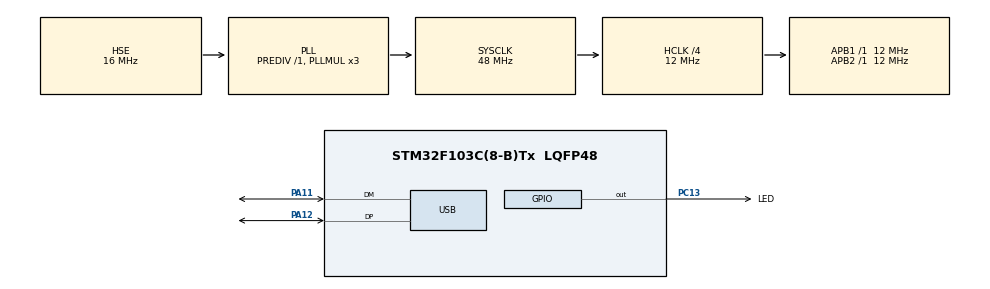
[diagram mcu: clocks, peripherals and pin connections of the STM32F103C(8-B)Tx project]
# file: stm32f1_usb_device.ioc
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FREERTOS.Tasks01=defaultTask,0,128,StartDefaultTask,Default
Mcu.Family=STM32F1
Mcu.Name=STM32F103C(8-B)Tx
Mcu.Package=LQFP48
NVIC.PriorityGroup=NVIC_PRIORITYGROUP_4
NVIC.TIM2_IRQn=true\:0\:0\:false\:false\:true\:false
NVIC.TIM3_IRQn=true\:0\:0\:false\:false\:true\:false
NVIC.TimeBase=TIM3_IRQn
NVIC.TimeBaseIP=TIM3
NVIC.USB_LP_CAN1_RX0_IRQn=true\:5\:0\:false\:false\:true\:true
PA11.Mode=Device
PA11.Signal=USB_DM
PA12.Mode=Device
PA12.Signal=USB_DP
PA13.Mode=Serial_Wire
PA13.Signal=SYS_JTMS-SWDIO
PA14.Mode=Serial_Wire
PA14.Signal=SYS_JTCK-SWCLK
PC13-TAMPER-RTC.GPIO_Label=LED
PC13-TAMPER-RTC.GPIO_Speed=GPIO_SPEED_FREQ_HIGH
PC13-TAMPER-RTC.Signal=GPIO_Output
PD0-OSC_IN.Mode=HSE-External-Oscillator
PD0-OSC_IN.Signal=RCC_OSC_IN
PD1-OSC_OUT.Mode=HSE-External-Oscillator
PD1-OSC_OUT.Signal=RCC_OSC_OUT
ProjectManager.HeapSize=0x200
ProjectManager.StackSize=0x400
ProjectManager.TargetToolchain=EWARM
RCC.AHBCLKDivider=RCC_SYSCLK_DIV4
RCC.AHBFreq_Value=12000000
RCC.APB1Freq_Value=12000000
RCC.APB1TimFreq_Value=12000000
RCC.APB2Freq_Value=12000000
RCC.APB2TimFreq_Value=12000000
RCC.HCLKFreq_Value=12000000
RCC.HSE_VALUE=16000000
RCC.HSIState=RCC_HSI_ON
RCC.PLLMUL=RCC_PLL_MUL3
RCC.PLLSourceVirtual=RCC_PLLSOURCE_HSE
RCC.SYSCLKFreq_VALUE=48000000
RCC.SYSCLKSource=RCC_SYSCLKSOURCE_PLLCLK
RCC.USBFreq_Value=48000000
TIM2.Period=500
TIM2.Prescaler=12000
USB_DEVICE.CLASS_NAME_FS=CDC
USB_DEVICE.USBD_HandleTypeDef=hUsbDeviceFS
USB_DEVICE.VirtualMode=Cdc
USB_DEVICE.VirtualModeFS=Cdc_FS
VP_FREERTOS_VS_ENABLE.Mode=Enabled
VP_SYS_VS_tim3.Mode=TIM3
VP_TIM2_VS_ClockSourceINT.Mode=Internal
VP_USB_DEVICE_VS_USB_DEVICE_CDC_FS.Mode=CDC_FS
board=stm32f1_usb_device

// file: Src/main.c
/**
  ******************************************************************************
  * File Name          : main.c
  * Description        : Main program body
  ******************************************************************************
  *
  * COPYRIGHT(c) 2016 STMicroelectronics
  *
  * Redistribution and use in source and binary forms, with or without modification,
  * are permitted provided that the following conditions are met:
  *   1. Redistributions of source code must retain the above copyright notice,
  *      this list of conditions and the following disclaimer.
  *   2. Redistributions in binary form must reproduce the above copyright notice,
  *      this list of conditions and the following disclaimer in the documentation
  *      and/or other materials provided with the distribution.
  *   3. Neither the name of STMicroelectronics nor the names of its contributors
  *      may be used to endorse or promote products derived from this software
  *      without specific prior written permission.
  *
  * THIS SOFTWARE IS PROVIDED BY THE COPYRIGHT HOLDERS AND CONTRIBUTORS "AS IS"
  * AND ANY EXPRESS OR IMPLIED WARRANTIES, INCLUDING, BUT NOT LIMITED TO, THE
  * IMPLIED WARRANTIES OF MERCHANTABILITY AND FITNESS FOR A PARTICULAR PURPOSE ARE
  * DISCLAIMED. IN NO EVENT SHALL THE COPYRIGHT HOLDER OR CONTRIBUTORS BE LIABLE
  * FOR ANY DIRECT, INDIRECT, INCIDENTAL, SPECIAL, EXEMPLARY, OR CONSEQUENTIAL
  * DAMAGES (INCLUDING, BUT NOT LIMITED TO, PROCUREMENT OF SUBSTITUTE GOODS OR
  * SERVICES; LOSS OF USE, DATA, OR PROFITS; OR BUSINESS INTERRUPTION) HOWEVER
  * CAUSED AND ON ANY THEORY OF LIABILITY, WHETHER IN CONTRACT, STRICT LIABILITY,
  * OR TORT (INCLUDING NEGLIGENCE OR OTHERWISE) ARISING IN ANY WAY OUT OF THE USE
  * OF THIS SOFTWARE, EVEN IF ADVISED OF THE POSSIBILITY OF SUCH DAMAGE.
  *
  ******************************************************************************
  */
#include "stm32f1xx_hal.h"
#include "cmsis_os.h"
#include "usb_device.h"

TIM_HandleTypeDef htim2;

osThreadId defaultTaskHandle;

/* USER CODE BEGIN PV */
/* Private variables ---------------------------------------------------------*/

/* USER CODE END PV */

void SystemClock_Config(void);
void Error_Handler(void);
static void MX_GPIO_Init(void);
static void MX_TIM2_Init(void);
void StartDefaultTask(void const * argument);

/* USER CODE BEGIN PFP */
/* Private function prototypes -----------------------------------------------*/

/* USER CODE END PFP */

int main(void)
{

	/* MCU Configuration----------------------------------------------------------*/

	/* Reset of all peripherals, Initializes the Flash interface and the Systick. */
	HAL_Init();

	/* Configure the system clock */
	SystemClock_Config();

	/* Initialize all configured peripherals */
	MX_GPIO_Init();
	MX_TIM2_Init();

	/* Create the thread(s) */
	/* definition and creation of defaultTask */
	osThreadDef(defaultTask, StartDefaultTask, osPriorityNormal, 0, 128);
	defaultTaskHandle = osThreadCreate(osThread(defaultTask), NULL);

	/* Start scheduler */
	osKernelStart();

	/* We should never get here as control is now taken by the scheduler */

	/* Infinite loop */
	while (1) {

	}

}

/** System Clock Configuration
*/
void SystemClock_Config(void)
{

	RCC_OscInitTypeDef RCC_OscInitStruct;
	RCC_ClkInitTypeDef RCC_ClkInitStruct;
	RCC_PeriphCLKInitTypeDef PeriphClkInit;

	RCC_OscInitStruct.OscillatorType = RCC_OSCILLATORTYPE_HSE;
	RCC_OscInitStruct.HSEState = RCC_HSE_ON;
	RCC_OscInitStruct.HSEPredivValue = RCC_HSE_PREDIV_DIV1;
	RCC_OscInitStruct.PLL.PLLState = RCC_PLL_ON;
	RCC_OscInitStruct.PLL.PLLSource = RCC_PLLSOURCE_HSE;
	RCC_OscInitStruct.PLL.PLLMUL = RCC_PLL_MUL3;
	if (HAL_RCC_OscConfig(&RCC_OscInitStruct) != HAL_OK) {
		Error_Handler();
	}

	RCC_ClkInitStruct.ClockType = RCC_CLOCKTYPE_HCLK|RCC_CLOCKTYPE_SYSCLK
								  |RCC_CLOCKTYPE_PCLK1|RCC_CLOCKTYPE_PCLK2;
	RCC_ClkInitStruct.SYSCLKSource = RCC_SYSCLKSOURCE_PLLCLK;
	RCC_ClkInitStruct.AHBCLKDivider = RCC_SYSCLK_DIV4;
	RCC_ClkInitStruct.APB1CLKDivider = RCC_HCLK_DIV1;
	RCC_ClkInitStruct.APB2CLKDivider = RCC_HCLK_DIV1;
	if (HAL_RCC_ClockConfig(&RCC_ClkInitStruct, FLASH_LATENCY_0) != HAL_OK) {
		Error_Handler();
	}

	PeriphClkInit.PeriphClockSelection = RCC_PERIPHCLK_USB;
	PeriphClkInit.UsbClockSelection = RCC_USBCLKSOURCE_PLL;
	if (HAL_RCCEx_PeriphCLKConfig(&PeriphClkInit) != HAL_OK) {
		Error_Handler();
	}

	HAL_SYSTICK_Config(HAL_RCC_GetHCLKFreq()/1000);

	HAL_SYSTICK_CLKSourceConfig(SYSTICK_CLKSOURCE_HCLK);

	/* SysTick_IRQn interrupt configuration */
	HAL_NVIC_SetPriority(SysTick_IRQn, 15, 0);
}

/* TIM2 init function */
static void MX_TIM2_Init(void)
{

	TIM_ClockConfigTypeDef sClockSourceConfig;
	TIM_MasterConfigTypeDef sMasterConfig;

	htim2.Instance = TIM2;
	htim2.Init.Prescaler = 12000;
	htim2.Init.CounterMode = TIM_COUNTERMODE_UP;
	htim2.Init.Period = 500;
	htim2.Init.ClockDivision = TIM_CLOCKDIVISION_DIV1;
	if (HAL_TIM_Base_Init(&htim2) != HAL_OK) {
		Error_Handler();
	}

	sClockSourceConfig.ClockSource = TIM_CLOCKSOURCE_INTERNAL;
	if (HAL_TIM_ConfigClockSource(&htim2, &sClockSourceConfig) != HAL_OK) {
		Error_Handler();
	}

	sMasterConfig.MasterOutputTrigger = TIM_TRGO_RESET;
	sMasterConfig.MasterSlaveMode = TIM_MASTERSLAVEMODE_DISABLE;
	if (HAL_TIMEx_MasterConfigSynchronization(&htim2, &sMasterConfig) != HAL_OK) {
		Error_Handler();
	}

	HAL_TIM_Base_Start_IT(&htim2);

}

/** Configure pins as
        * Analog
        * Input
        * Output
        * EVENT_OUT
        * EXTI
        * Free pins are configured automatically as Analog (this feature is enabled through
        * the Code Generation settings)
*/
static void MX_GPIO_Init(void)
{

	GPIO_InitTypeDef GPIO_InitStruct;

	/* GPIO Ports Clock Enable */
	__HAL_RCC_GPIOC_CLK_ENABLE();
	__HAL_RCC_GPIOD_CLK_ENABLE();
	__HAL_RCC_GPIOA_CLK_ENABLE();
	__HAL_RCC_GPIOB_CLK_ENABLE();

	/*Configure GPIO pin Output Level */
	HAL_GPIO_WritePin(LED_GPIO_Port, LED_Pin, GPIO_PIN_RESET);

	/*Configure GPIO pin : LED_Pin */
	GPIO_InitStruct.Pin = LED_Pin;
	GPIO_InitStruct.Mode = GPIO_MODE_OUTPUT_PP;
	GPIO_InitStruct.Speed = GPIO_SPEED_FREQ_HIGH;
	HAL_GPIO_Init(LED_GPIO_Port, &GPIO_InitStruct);

	/*Configure GPIO pins : PC14 PC15 */
	GPIO_InitStruct.Pin = GPIO_PIN_14|GPIO_PIN_15;
	GPIO_InitStruct.Mode = GPIO_MODE_ANALOG;
	HAL_GPIO_Init(GPIOC, &GPIO_InitStruct);

	/*Configure GPIO pins : PA0 PA1 PA2 PA3
	                         PA4 PA5 PA6 PA7
	                         PA8 PA9 PA10 PA15 */
	GPIO_InitStruct.Pin = GPIO_PIN_0|GPIO_PIN_1|GPIO_PIN_2|GPIO_PIN_3
						  |GPIO_PIN_4|GPIO_PIN_5|GPIO_PIN_6|GPIO_PIN_7
						  |GPIO_PIN_8|GPIO_PIN_9|GPIO_PIN_10|GPIO_PIN_15;
	GPIO_InitStruct.Mode = GPIO_MODE_ANALOG;
	HAL_GPIO_Init(GPIOA, &GPIO_InitStruct);

	/*Configure GPIO pins : PB0 PB1 PB2 PB10
	                         PB11 PB12 PB13 PB14
	                         PB15 PB3 PB4 PB5
	                         PB6 PB7 PB8 PB9 */
	GPIO_InitStruct.Pin = GPIO_PIN_0|GPIO_PIN_1|GPIO_PIN_2|GPIO_PIN_10
						  |GPIO_PIN_11|GPIO_PIN_12|GPIO_PIN_13|GPIO_PIN_14
						  |GPIO_PIN_15|GPIO_PIN_3|GPIO_PIN_4|GPIO_PIN_5
						  |GPIO_PIN_6|GPIO_PIN_7|GPIO_PIN_8|GPIO_PIN_9;
	GPIO_InitStruct.Mode = GPIO_MODE_ANALOG;
	HAL_GPIO_Init(GPIOB, &GPIO_InitStruct);

}

/* StartDefaultTask function */
void StartDefaultTask(void const * argument)
{
	/* init code for USB_DEVICE */
	MX_USB_DEVICE_Init();

	/* USER CODE BEGIN 5 */
	/* Infinite loop */
	for (;;) {
		uint8_t Buf[] = "test";
		while (CDC_Transmit_FS(Buf, 4) == USBD_BUSY)
			HAL_Delay(1);
		//HAL_GPIO_TogglePin(GPIOC, GPIO_PIN_13);
		HAL_Delay(500);

	}
	/* USER CODE END 5 */
}

void HAL_TIM_PeriodElapsedCallback(TIM_HandleTypeDef *htim)
{
	if (htim->Instance == TIM3) {
		HAL_IncTick();
	}
	/* USER CODE BEGIN Callback 1 */

	if (htim->Instance == TIM2) {
		HAL_GPIO_TogglePin(GPIOC, GPIO_PIN_13);
	}

	/* USER CODE END Callback 1 */
}

void Error_Handler(void)
{
	while (1) {
	}
}

/************************ (C) COPYRIGHT STMicroelectronics *****END OF FILE****/
